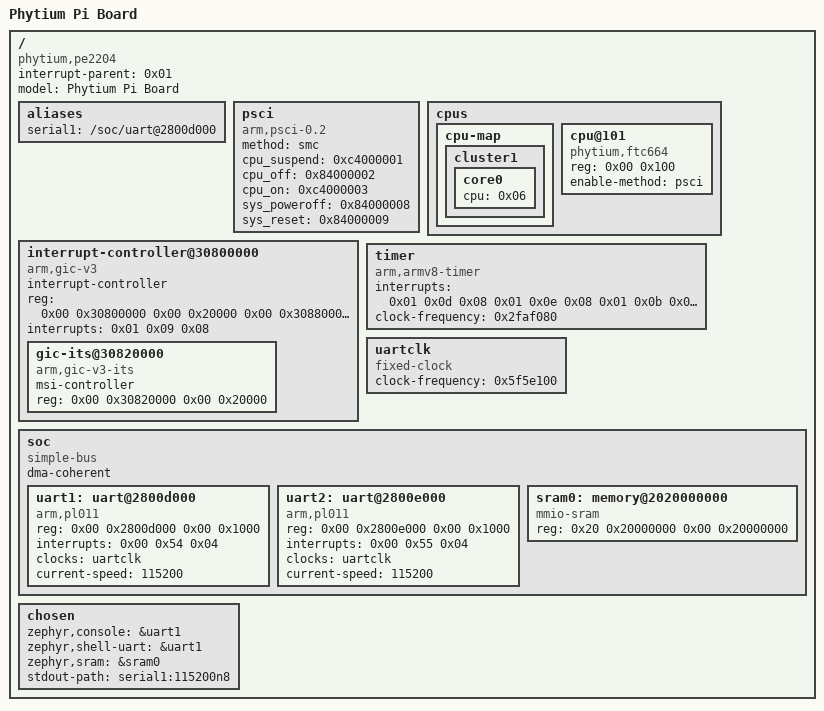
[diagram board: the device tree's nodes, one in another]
/dts-v1/;

/memreserve/ 0x0000000080000000 0x0000000000010000;
/ {
	compatible = "phytium,pe2204";
	interrupt-parent = <0x01>;
	#address-cells = <0x02>;
	#size-cells = <0x02>;
	model = "Phytium Pi Board";

	aliases {
		serial1 = "/soc/uart@2800d000";
	};

	psci {
		compatible = "arm,psci-0.2";
		method = "smc";
		cpu_suspend = <0xc4000001>;
		cpu_off = <0x84000002>;
		cpu_on = <0xc4000003>;
		sys_poweroff = <0x84000008>;
		sys_reset = <0x84000009>;
	};

	cpus {
		#address-cells = <0x02>;
		#size-cells = <0x00>;

		cpu-map {
			cluster1 {
				core0 {
					cpu = <0x06>;
				};
			};
		};

		cpu@101 {
			device_type = "cpu";
			compatible = "phytium,ftc664\0arm,armv8";
			reg = <0x00 0x100>;
			enable-method = "psci";
			phandle = <0x06>;
		};
	};

	interrupt-controller@30800000 {
		compatible = "arm,gic-v3";
		#interrupt-cells = <0x03>;
		#address-cells = <0x02>;
		#size-cells = <0x02>;
		ranges;
		interrupt-controller;
		reg = <0x00 0x30800000 0x00 0x20000
		       0x00 0x30880000 0x00 0x80000
		       0x00 0x30840000 0x00 0x10000
		       0x00 0x30850000 0x00 0x10000
		       0x00 0x30860000 0x00 0x10000>;
		interrupts = <0x01 0x09 0x08>;
		phandle = <0x01>;

		gic-its@30820000 {
			compatible = "arm,gic-v3-its";
			msi-controller;
			reg = <0x00 0x30820000 0x00 0x20000>;
		};
	};

	timer {
		compatible = "arm,armv8-timer";
		interrupts = <0x01 0x0d 0x08 0x01 0x0e 0x08 0x01 0x0b 0x08 0x01 0x0a 0x08>;
		clock-frequency = <0x2faf080>;
	};

	uartclk: uartclk {
		compatible = "fixed-clock";
		#clock-cells = <0x00>;
		clock-frequency = <0x5f5e100>;
		phandle = <0x0c>;
	};

	soc {
		compatible = "simple-bus";
		#address-cells = <0x02>;
		#size-cells = <0x02>;
		dma-coherent;
		ranges;

		uart1: uart@2800d000 {
			compatible = "arm,pl011\0arm,primecell";
			reg = <0x00 0x2800d000 0x00 0x1000>;
			interrupts = <0x00 0x54 0x04>;
			clocks = <&uartclk>;
			current-speed = <115200>;
			status = "okay";
		};

		uart2: uart@2800e000 {
			compatible = "arm,pl011\0arm,primecell";
			reg = <0x00 0x2800e000 0x00 0x1000>;
			interrupts = <0x00 0x55 0x04>;
			clocks = <&uartclk>;
			current-speed = <115200>;
			status = "okay";
		};

		sram0: memory@2020000000 {
			device_type = "memory";
			compatible = "mmio-sram";
			reg = <0x20 0x20000000 0x00 0x20000000>;
		};
	};

	chosen {
		zephyr,console = &uart1;
		zephyr,shell-uart = &uart1;
		zephyr,sram = &sram0;
		stdout-path = "serial1:115200n8";
	};
};
